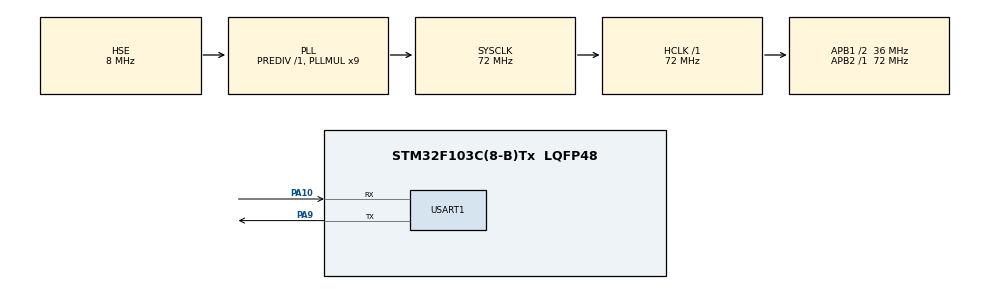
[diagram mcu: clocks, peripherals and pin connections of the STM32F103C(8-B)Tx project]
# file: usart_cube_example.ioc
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Mcu.Family=STM32F1
RCC.PLLSourceVirtual=RCC_PLLSOURCE_HSE
NVIC.DMA1_Channel5_IRQn=true\:1\:0\:true\:false\:true\:false\:true
PD1-OSC_OUT.Mode=HSE-External-Oscillator
Dma.USART1_RX.0.PeriphDataAlignment=DMA_PDATAALIGN_BYTE
PA10.Mode=Asynchronous
PD0-OSC_IN.Signal=RCC_OSC_IN
RCC.APB1CLKDivider=RCC_HCLK_DIV2
RCC.SYSCLKSource=RCC_SYSCLKSOURCE_PLLCLK
ProjectManager.StackSize=0x400
PD1-OSC_OUT.Signal=RCC_OSC_OUT
PA13.Signal=SYS_JTMS-SWDIO
PA9.Mode=Asynchronous
ProjectManager.TargetToolchain=MDK-ARM V5
Dma.USART1_RX.0.Direction=DMA_PERIPH_TO_MEMORY
RCC.HCLKFreq_Value=72000000
RCC.APB2TimFreq_Value=72000000
PA9.Signal=USART1_TX
RCC.USBFreq_Value=72000000
RCC.AHBFreq_Value=72000000
Dma.USART1_RX.0.PeriphInc=DMA_PINC_DISABLE
Dma.USART1_RX.0.Priority=DMA_PRIORITY_LOW
PD0-OSC_IN.Mode=HSE-External-Oscillator
board=custom
RCC.PLLMUL=RCC_PLL_MUL9
RCC.APB2Freq_Value=72000000
PA14.Mode=Serial_Wire
Dma.USART1_RX.0.MemDataAlignment=DMA_MDATAALIGN_BYTE
Dma.USART1_RX.0.MemInc=DMA_MINC_ENABLE
PA13.Mode=Serial_Wire
Mcu.Name=STM32F103C(8-B)Tx
RCC.SYSCLKFreq_VALUE=72000000
Mcu.Package=LQFP48
USART1.VirtualMode=VM_ASYNC
PA10.Signal=USART1_RX
PA14.Signal=SYS_JTCK-SWCLK
ProjectManager.HeapSize=0x200
NVIC.PriorityGroup=NVIC_PRIORITYGROUP_4
RCC.APB1TimFreq_Value=72000000
Dma.USART1_RX.0.Mode=DMA_CIRCULAR
NVIC.USART1_IRQn=true\:1\:0\:true\:false\:true\:true\:true
Dma.Request0=USART1_RX
RCC.APB1Freq_Value=36000000
Dma.USART1_RX.0.Instance=DMA1_Channel5

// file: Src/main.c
/* USER CODE BEGIN Header */
/**
  ******************************************************************************
    @Copyright (C), 2020, Jomse Qin,JNU.
    @FileName: main.c
    @Author:Jomse   Version:1.0   Date:2020-05-11
    @Description: 1.usart1 transmit and dma interrupt receive.
                  2.΢�Ź��ںţ�����Ҷ�Ĵ�(xsqj74).
    @Version: <version > 1.0.
    @Function List: HAL_UART_RxCpltCallback.
    @History: 2020-05-11 create this project and build it.
    @<author> Jomse <time> 2020-05-11 <version > 1.0
    Jomse 2020-05-11 1.0 build this moudle
  ******************************************************************************
  */
/* USER CODE END Header */

#include "main.h"
#include "dma.h"
#include "usart.h"
#include "gpio.h"

/* USER CODE BEGIN Includes */
#include <stdio.h>
#include <string.h>
/* USER CODE END Includes */

/* USER CODE BEGIN PV */
volatile uint8_t usart1_read_data[10];
/* USER CODE END PV */

void SystemClock_Config(void);

/* USER CODE BEGIN 0 */
void HAL_UART_RxCpltCallback(UART_HandleTypeDef *huart)
{
	if(huart->Instance == USART1)
	{
		//usart1_print("call back data:%s\r\n",usart1_read_data);
		HAL_UART_Transmit(&huart1,(uint8_t *)"hello usart\n",strlen("hello usart\n"),0xff);
		HAL_Delay(3);
	}
}
/* USER CODE END 0 */

int main(void)
{

  /* MCU Configuration--------------------------------------------------------*/

  /* Reset of all peripherals, Initializes the Flash interface and the Systick. */
  HAL_Init();

  /* Configure the system clock */
  SystemClock_Config();

  /* Initialize all configured peripherals */
  MX_GPIO_Init();
  MX_DMA_Init();
  MX_USART1_UART_Init();
  /* USER CODE BEGIN 2 */
  HAL_UART_Receive_DMA((UART_HandleTypeDef *)&huart1,(uint8_t *)usart1_read_data, (uint16_t) 1);
  /* USER CODE END 2 */

  /* Infinite loop */
  while (1)
  {
   // HAL_UART_Transmit(&huart1,(uint8_t *)"hello usart\n",strlen("hello usart\n"),0xff);
  }
}

void SystemClock_Config(void)
{
  RCC_OscInitTypeDef RCC_OscInitStruct = {0};
  RCC_ClkInitTypeDef RCC_ClkInitStruct = {0};

  /** Initializes the CPU, AHB and APB busses clocks
  */
  RCC_OscInitStruct.OscillatorType = RCC_OSCILLATORTYPE_HSE;
  RCC_OscInitStruct.HSEState = RCC_HSE_ON;
  RCC_OscInitStruct.HSEPredivValue = RCC_HSE_PREDIV_DIV1;
  RCC_OscInitStruct.HSIState = RCC_HSI_ON;
  RCC_OscInitStruct.PLL.PLLState = RCC_PLL_ON;
  RCC_OscInitStruct.PLL.PLLSource = RCC_PLLSOURCE_HSE;
  RCC_OscInitStruct.PLL.PLLMUL = RCC_PLL_MUL9;
  if (HAL_RCC_OscConfig(&RCC_OscInitStruct) != HAL_OK)
  {
    Error_Handler();
  }
  /** Initializes the CPU, AHB and APB busses clocks
  */
  RCC_ClkInitStruct.ClockType = RCC_CLOCKTYPE_HCLK|RCC_CLOCKTYPE_SYSCLK
                              |RCC_CLOCKTYPE_PCLK1|RCC_CLOCKTYPE_PCLK2;
  RCC_ClkInitStruct.SYSCLKSource = RCC_SYSCLKSOURCE_PLLCLK;
  RCC_ClkInitStruct.AHBCLKDivider = RCC_SYSCLK_DIV1;
  RCC_ClkInitStruct.APB1CLKDivider = RCC_HCLK_DIV2;
  RCC_ClkInitStruct.APB2CLKDivider = RCC_HCLK_DIV1;

  if (HAL_RCC_ClockConfig(&RCC_ClkInitStruct, FLASH_LATENCY_2) != HAL_OK)
  {
    Error_Handler();
  }
}

void Error_Handler(void)
{
}

/************************ (C) COPYRIGHT STMicroelectronics *****END OF FILE****/
